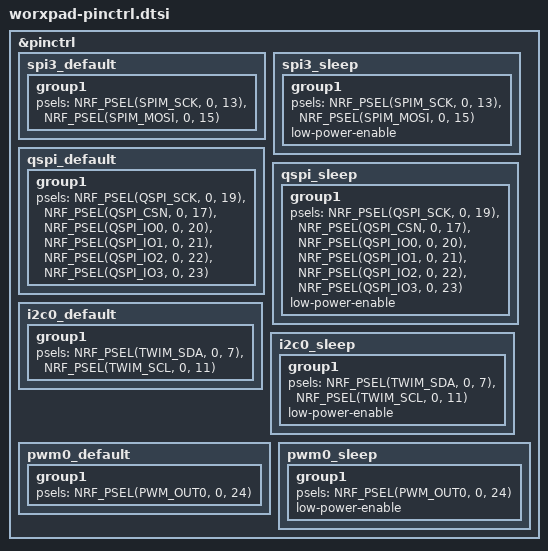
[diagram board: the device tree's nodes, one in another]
/*
 * SPDX-License-Identifier: MIT
 *
 * worxpad peripheral pins. Every pin here must match [pinmap] in board.toml; tools/check_pins.py
 * compares them. Change board.toml first, then this file.
 */

&pinctrl {
    /* Display, SPIM3 (the only nRF52840 SPI master above 8 MHz, mcu-radio 7.5). Write-only: no MISO. */
    spi3_default: spi3_default {
        group1 {
            psels = <NRF_PSEL(SPIM_SCK, 0, 13)>, <NRF_PSEL(SPIM_MOSI, 0, 15)>;
        };
    };
    spi3_sleep: spi3_sleep {
        group1 {
            psels = <NRF_PSEL(SPIM_SCK, 0, 13)>, <NRF_PSEL(SPIM_MOSI, 0, 15)>;
            low-power-enable;
        };
    };

    /* W25Q128JV icon flash on QSPI (mcu-radio 7.2, nRF52840 DK pin set). */
    qspi_default: qspi_default {
        group1 {
            psels = <NRF_PSEL(QSPI_SCK, 0, 19)>, <NRF_PSEL(QSPI_CSN, 0, 17)>,
                    <NRF_PSEL(QSPI_IO0, 0, 20)>, <NRF_PSEL(QSPI_IO1, 0, 21)>,
                    <NRF_PSEL(QSPI_IO2, 0, 22)>, <NRF_PSEL(QSPI_IO3, 0, 23)>;
        };
    };
    qspi_sleep: qspi_sleep {
        group1 {
            psels = <NRF_PSEL(QSPI_SCK, 0, 19)>, <NRF_PSEL(QSPI_CSN, 0, 17)>,
                    <NRF_PSEL(QSPI_IO0, 0, 20)>, <NRF_PSEL(QSPI_IO1, 0, 21)>,
                    <NRF_PSEL(QSPI_IO2, 0, 22)>, <NRF_PSEL(QSPI_IO3, 0, 23)>;
            low-power-enable;
        };
    };

    /* MAX17048 fuel gauge. 4.7 kOhm pull-ups to 3V3 sit on the board (power 9). */
    i2c0_default: i2c0_default {
        group1 {
            psels = <NRF_PSEL(TWIM_SDA, 0, 7)>, <NRF_PSEL(TWIM_SCL, 0, 11)>;
        };
    };
    i2c0_sleep: i2c0_sleep {
        group1 {
            psels = <NRF_PSEL(TWIM_SDA, 0, 7)>, <NRF_PSEL(TWIM_SCL, 0, 11)>;
            low-power-enable;
        };
    };

    /* Backlight: gate of the AO3400A low-side switch (display 6.3). */
    pwm0_default: pwm0_default {
        group1 {
            psels = <NRF_PSEL(PWM_OUT0, 0, 24)>;
        };
    };
    pwm0_sleep: pwm0_sleep {
        group1 {
            psels = <NRF_PSEL(PWM_OUT0, 0, 24)>;
            low-power-enable;
        };
    };
};
